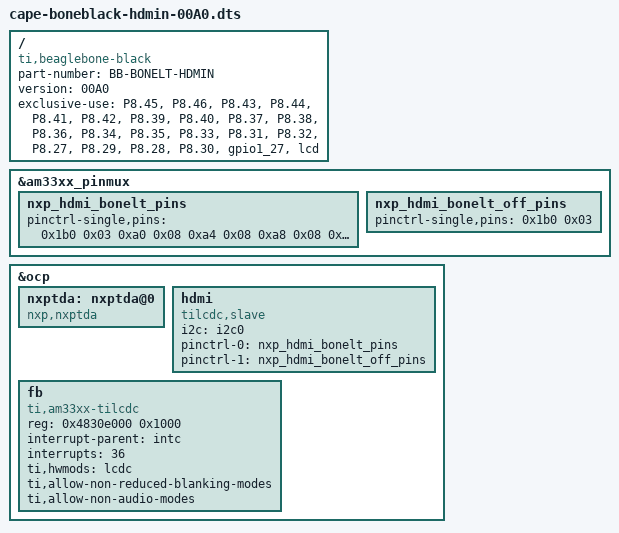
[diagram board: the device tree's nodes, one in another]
/*
* Copyright (C) 2012 Texas Instruments Incorporated - http://www.ti.com/
*
* This program is free software; you can redistribute it and/or modify
* it under the terms of the GNU General Public License version 2 as
* published by the Free Software Foundation.
*/
/dts-v1/;
/plugin/;

/ {
	compatible = "ti,beaglebone-black";
	part-number = "BB-BONELT-HDMIN";	/* No audio */
	version = "00A0";

	/* state the resources this cape uses */
	exclusive-use =
		/* the pin header uses */
		"P8.45",	/* lcd: lcd_data0 */
		"P8.46",	/* lcd: lcd_data1 */
		"P8.43",	/* lcd: lcd_data2 */
		"P8.44",	/* lcd: lcd_data3 */
		"P8.41",	/* lcd: lcd_data4 */
		"P8.42",	/* lcd: lcd_data5 */
		"P8.39",	/* lcd: lcd_data6 */
		"P8.40",	/* lcd: lcd_data7 */
		"P8.37",	/* lcd: lcd_data8 */
		"P8.38",	/* lcd: lcd_data9 */
		"P8.36",	/* lcd: lcd_data10 */
		"P8.34",	/* lcd: lcd_data11 */
		"P8.35",	/* lcd: lcd_data12 */
		"P8.33",	/* lcd: lcd_data13 */
		"P8.31",	/* lcd: lcd_data14 */
		"P8.32",	/* lcd: lcd_data15 */
		"P8.27",	/* lcd: lcd_vsync */
		"P8.29",	/* lcd: lcd_hsync */
		"P8.28",	/* lcd: lcd_pclk */
		"P8.30",	/* lcd: lcd_ac_bias_en */
		/* the hardware IP uses */
		"gpio1_27",
		"lcd";

	fragment@0 {
		target = <&am33xx_pinmux>;
		__overlay__ {
			nxp_hdmi_bonelt_pins: nxp_hdmi_bonelt_pins {
				pinctrl-single,pins = <
					0x1b0 0x03      /* xdma_event_intr0, OMAP_MUX_MODE3 | AM33XX_PIN_OUTPUT */
					0xa0 0x08       /* lcd_data0.lcd_data0, OMAP_MUX_MODE0 | AM33XX_PIN_OUTPUT | AM33XX_PULL_DISA */
					0xa4 0x08       /* lcd_data1.lcd_data1, OMAP_MUX_MODE0 | AM33XX_PIN_OUTPUT | AM33XX_PULL_DISA */
					0xa8 0x08       /* lcd_data2.lcd_data2, OMAP_MUX_MODE0 | AM33XX_PIN_OUTPUT | AM33XX_PULL_DISA */
					0xac 0x08       /* lcd_data3.lcd_data3, OMAP_MUX_MODE0 | AM33XX_PIN_OUTPUT | AM33XX_PULL_DISA */
					0xb0 0x08       /* lcd_data4.lcd_data4, OMAP_MUX_MODE0 | AM33XX_PIN_OUTPUT | AM33XX_PULL_DISA */
					0xb4 0x08       /* lcd_data5.lcd_data5, OMAP_MUX_MODE0 | AM33XX_PIN_OUTPUT | AM33XX_PULL_DISA */
					0xb8 0x08       /* lcd_data6.lcd_data6, OMAP_MUX_MODE0 | AM33XX_PIN_OUTPUT | AM33XX_PULL_DISA */
					0xbc 0x08       /* lcd_data7.lcd_data7, OMAP_MUX_MODE0 | AM33XX_PIN_OUTPUT | AM33XX_PULL_DISA */
					0xc0 0x08       /* lcd_data8.lcd_data8, OMAP_MUX_MODE0 | AM33XX_PIN_OUTPUT | AM33XX_PULL_DISA */
					0xc4 0x08       /* lcd_data9.lcd_data9, OMAP_MUX_MODE0 | AM33XX_PIN_OUTPUT | AM33XX_PULL_DISA */
					0xc8 0x08       /* lcd_data10.lcd_data10, OMAP_MUX_MODE0 | AM33XX_PIN_OUTPUT | AM33XX_PULL_DISA */
					0xcc 0x08       /* lcd_data11.lcd_data11, OMAP_MUX_MODE0 | AM33XX_PIN_OUTPUT | AM33XX_PULL_DISA */
					0xd0 0x08       /* lcd_data12.lcd_data12, OMAP_MUX_MODE0 | AM33XX_PIN_OUTPUT | AM33XX_PULL_DISA */
					0xd4 0x08       /* lcd_data13.lcd_data13, OMAP_MUX_MODE0 | AM33XX_PIN_OUTPUT | AM33XX_PULL_DISA */
					0xd8 0x08       /* lcd_data14.lcd_data14, OMAP_MUX_MODE0 | AM33XX_PIN_OUTPUT | AM33XX_PULL_DISA */
					0xdc 0x08       /* lcd_data15.lcd_data15, OMAP_MUX_MODE0 | AM33XX_PIN_OUTPUT | AM33XX_PULL_DISA */
					0xe0 0x00       /* lcd_vsync.lcd_vsync, OMAP_MUX_MODE0 | AM33XX_PIN_OUTPUT */
					0xe4 0x00       /* lcd_hsync.lcd_hsync, OMAP_MUX_MODE0 | AM33XX_PIN_OUTPUT */
					0xe8 0x00       /* lcd_pclk.lcd_pclk, OMAP_MUX_MODE0 | AM33XX_PIN_OUTPUT */
					0xec 0x00       /* lcd_ac_bias_en.lcd_ac_bias_en, OMAP_MUX_MODE0 | AM33XX_PIN_OUTPUT */
				>;
			};
			nxp_hdmi_bonelt_off_pins: nxp_hdmi_bonelt_off_pins {
				pinctrl-single,pins = <
					0x1b0 0x03      /* xdma_event_intr0, OMAP_MUX_MODE3 | AM33XX_PIN_OUTPUT */
				>;
			};
		};
	};

	fragment@2 {
		target = <&ocp>;
		__overlay__ {

			/* avoid stupid warning */
			#address-cells = <1>;
			#size-cells = <1>;

			nxptda: nxptda@0 {
			       compatible = "nxp,nxptda";
			       status = "okay";
			};

			hdmi {
				compatible = "tilcdc,slave";
				i2c = <&i2c0>;
				pinctrl-names = "default", "off";
				pinctrl-0 = <&nxp_hdmi_bonelt_pins>;
				pinctrl-1 = <&nxp_hdmi_bonelt_off_pins>;
			};

			fb {
				compatible = "ti,am33xx-tilcdc";
				reg = <0x4830e000 0x1000>;
				interrupt-parent = <&intc>;
				interrupts = <36>;
				ti,hwmods = "lcdc";
				ti,allow-non-reduced-blanking-modes;
				ti,allow-non-audio-modes;
			};

		};
	};
};
